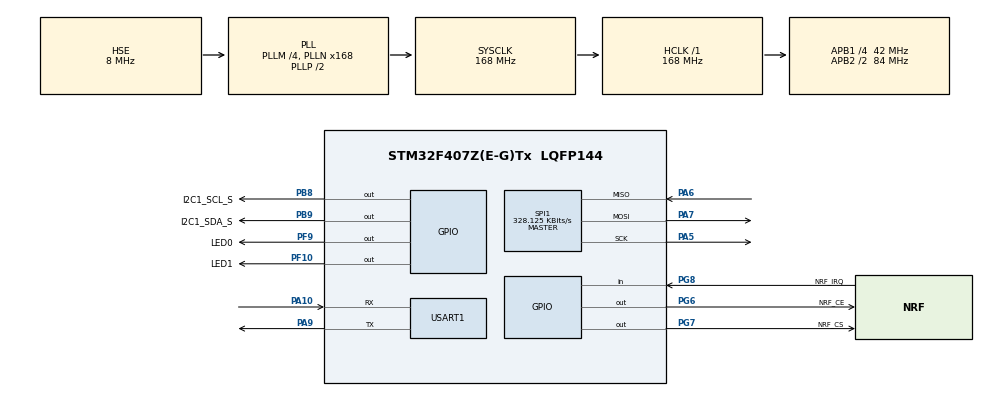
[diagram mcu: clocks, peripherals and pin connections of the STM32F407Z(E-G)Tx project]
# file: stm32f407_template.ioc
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Dma.Request0=USART1_RX
Dma.Request1=USART1_TX
Dma.USART1_RX.0.Direction=DMA_PERIPH_TO_MEMORY
Dma.USART1_RX.0.FIFOMode=DMA_FIFOMODE_DISABLE
Dma.USART1_RX.0.Instance=DMA2_Stream2
Dma.USART1_RX.0.MemDataAlignment=DMA_MDATAALIGN_BYTE
Dma.USART1_RX.0.MemInc=DMA_MINC_ENABLE
Dma.USART1_RX.0.Mode=DMA_CIRCULAR
Dma.USART1_RX.0.PeriphDataAlignment=DMA_PDATAALIGN_BYTE
Dma.USART1_RX.0.PeriphInc=DMA_PINC_DISABLE
Dma.USART1_RX.0.Priority=DMA_PRIORITY_HIGH
Dma.USART1_TX.1.Direction=DMA_MEMORY_TO_PERIPH
Dma.USART1_TX.1.FIFOMode=DMA_FIFOMODE_DISABLE
Dma.USART1_TX.1.Instance=DMA2_Stream7
Dma.USART1_TX.1.MemDataAlignment=DMA_MDATAALIGN_BYTE
Dma.USART1_TX.1.MemInc=DMA_MINC_ENABLE
Dma.USART1_TX.1.Mode=DMA_NORMAL
Dma.USART1_TX.1.PeriphDataAlignment=DMA_PDATAALIGN_BYTE
Dma.USART1_TX.1.PeriphInc=DMA_PINC_DISABLE
Dma.USART1_TX.1.Priority=DMA_PRIORITY_MEDIUM
FREERTOS.INCLUDE_vTaskDelayUntil=1
FREERTOS.Tasks01=defaultTask,0,128,StartDefaultTask,Default,NULL,Dynamic,NULL,NULL
FREERTOS.configMINIMAL_STACK_SIZE=64
Mcu.Family=STM32F4
Mcu.Name=STM32F407Z(E-G)Tx
Mcu.Package=LQFP144
NVIC.DMA2_Stream2_IRQn=true\:5\:0\:false\:false\:true\:true\:false\:true\:true
NVIC.DMA2_Stream7_IRQn=true\:5\:0\:false\:false\:true\:true\:false\:true\:true
NVIC.PriorityGroup=NVIC_PRIORITYGROUP_4
NVIC.TIM6_DAC_IRQn=true\:15\:0\:false\:false\:true\:false\:false\:true\:true
NVIC.TIM7_IRQn=true\:5\:0\:false\:false\:true\:true\:true\:true\:true
NVIC.TimeBase=TIM6_DAC_IRQn
NVIC.TimeBaseIP=TIM6
NVIC.USART1_IRQn=true\:5\:0\:false\:false\:true\:true\:true\:true\:true
PA10.Mode=Asynchronous
PA10.Signal=USART1_RX
PA13.Mode=Serial_Wire
PA13.Signal=SYS_JTMS-SWDIO
PA14.Mode=Serial_Wire
PA14.Signal=SYS_JTCK-SWCLK
PA5.Mode=Full_Duplex_Master
PA5.Signal=SPI1_SCK
PA6.Mode=Full_Duplex_Master
PA6.Signal=SPI1_MISO
PA7.Mode=Full_Duplex_Master
PA7.Signal=SPI1_MOSI
PA9.Mode=Asynchronous
PA9.Signal=USART1_TX
PB8.GPIO_Label=I2C1_SCL_S
PB8.GPIO_PuPd=GPIO_PULLUP
PB8.GPIO_Speed=GPIO_SPEED_FREQ_HIGH
PB8.PinState=GPIO_PIN_SET
PB8.Signal=GPIO_Output
PB9.GPIO_Label=I2C1_SDA_S
PB9.GPIO_PuPd=GPIO_PULLUP
PB9.GPIO_Speed=GPIO_SPEED_FREQ_HIGH
PB9.PinState=GPIO_PIN_SET
PB9.Signal=GPIO_Output
PF10.GPIO_Label=LED1
PF10.GPIO_PuPd=GPIO_PULLUP
PF10.GPIO_Speed=GPIO_SPEED_FREQ_HIGH
PF10.PinState=GPIO_PIN_SET
PF10.Signal=GPIO_Output
PF9.GPIO_Label=LED0
PF9.GPIO_ModeDefaultOutputPP=GPIO_MODE_OUTPUT_PP
PF9.GPIO_PuPd=GPIO_PULLUP
PF9.GPIO_Speed=GPIO_SPEED_FREQ_HIGH
PF9.PinState=GPIO_PIN_SET
PF9.Signal=GPIO_Output
PG6.GPIO_Label=NRF_CE
PG6.GPIO_PuPd=GPIO_PULLUP
PG6.GPIO_Speed=GPIO_SPEED_FREQ_HIGH
PG6.Signal=GPIO_Output
PG7.GPIO_Label=NRF_CS
PG7.GPIO_PuPd=GPIO_PULLUP
PG7.GPIO_Speed=GPIO_SPEED_FREQ_HIGH
PG7.PinState=GPIO_PIN_SET
PG7.Signal=GPIO_Output
PG8.GPIO_Label=NRF_IRQ
PG8.GPIO_PuPd=GPIO_PULLUP
PG8.Signal=GPIO_Input
PH0-OSC_IN.Mode=HSE-External-Oscillator
PH0-OSC_IN.Signal=RCC_OSC_IN
PH1-OSC_OUT.Mode=HSE-External-Oscillator
PH1-OSC_OUT.Signal=RCC_OSC_OUT
ProjectManager.HeapSize=0x200
ProjectManager.StackSize=0x400
ProjectManager.TargetToolchain=MDK-ARM V5.32
RCC.48MHZClocksFreq_Value=84000000
RCC.AHBFreq_Value=168000000
RCC.APB1CLKDivider=RCC_HCLK_DIV4
RCC.APB1Freq_Value=42000000
RCC.APB1TimFreq_Value=84000000
RCC.APB2CLKDivider=RCC_HCLK_DIV2
RCC.APB2Freq_Value=84000000
RCC.APB2TimFreq_Value=168000000
RCC.CortexFreq_Value=168000000
RCC.HCLKFreq_Value=168000000
RCC.HSE_VALUE=8000000
RCC.HSI_VALUE=16000000
RCC.LSE_VALUE=32768
RCC.PLLM=4
RCC.PLLN=168
RCC.PLLSourceVirtual=RCC_PLLSOURCE_HSE
RCC.SYSCLKFreq_VALUE=168000000
RCC.SYSCLKSource=RCC_SYSCLKSOURCE_PLLCLK
RCC.VCOOutputFreq_Value=336000000
SPI1.BaudRatePrescaler=SPI_BAUDRATEPRESCALER_256
SPI1.CLKPhase=SPI_PHASE_2EDGE
SPI1.CalculateBaudRate=328.125 KBits/s
SPI1.Direction=SPI_DIRECTION_2LINES
SPI1.Mode=SPI_MODE_MASTER
SPI1.VirtualType=VM_MASTER
TIM7.Prescaler=83
USART1.VirtualMode=VM_ASYNC
VP_FREERTOS_VS_CMSIS_V1.Mode=CMSIS_V1
VP_SYS_VS_tim6.Mode=TIM6
VP_TIM7_VS_ClockSourceINT.Mode=Enable_Timer
board=custom

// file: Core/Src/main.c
/* USER CODE BEGIN Header */
/**
  ******************************************************************************
  * @file           : main.c
  * @brief          : Main program body
  ******************************************************************************
  * @attention
  *
  * Copyright (c) 2023 STMicroelectronics.
  * All rights reserved.
  *
  * This software is licensed under terms that can be found in the LICENSE file
  * in the root directory of this software component.
  * If no LICENSE file comes with this software, it is provided AS-IS.
  *
  ******************************************************************************
  */
/* USER CODE END Header */
#include "main.h"
#include "cmsis_os.h"

/* USER CODE BEGIN Includes */
#include "system_start.h"
/* USER CODE END Includes */

osThreadId defaultTaskHandle;

void SystemClock_Config(void);
static void MX_GPIO_Init(void);
static void MX_DMA_Init(void);
static void MX_TIM7_Init(void);
static void MX_USART1_UART_Init(void);
static void MX_SPI1_Init(void);
void StartDefaultTask(void const * argument);

int main(void)
{

  /* MCU Configuration--------------------------------------------------------*/

  /* Reset of all peripherals, Initializes the Flash interface and the Systick. */
  HAL_Init();

  /* Configure the system clock */
  SystemClock_Config();

  /* Initialize all configured peripherals */
  MX_GPIO_Init();
  MX_DMA_Init();
  MX_TIM7_Init();
  MX_USART1_UART_Init();
  MX_SPI1_Init();
  /* USER CODE BEGIN 2 */
	System_Init();
  /* USER CODE END 2 */

  /* Create the thread(s) */
  /* definition and creation of defaultTask */
  osThreadDef(defaultTask, StartDefaultTask, osPriorityNormal, 0, 128);
  defaultTaskHandle = osThreadCreate(osThread(defaultTask), NULL);

  /* Start scheduler */
  osKernelStart();

  /* We should never get here as control is now taken by the scheduler */
  /* Infinite loop */
  while (1)
  {

  }
}

void SystemClock_Config(void)
{
  RCC_OscInitTypeDef RCC_OscInitStruct = {0};
  RCC_ClkInitTypeDef RCC_ClkInitStruct = {0};

  /** Configure the main internal regulator output voltage
  */
  __HAL_RCC_PWR_CLK_ENABLE();
  __HAL_PWR_VOLTAGESCALING_CONFIG(PWR_REGULATOR_VOLTAGE_SCALE1);

  /** Initializes the RCC Oscillators according to the specified parameters
  * in the RCC_OscInitTypeDef structure.
  */
  RCC_OscInitStruct.OscillatorType = RCC_OSCILLATORTYPE_HSE;
  RCC_OscInitStruct.HSEState = RCC_HSE_ON;
  RCC_OscInitStruct.PLL.PLLState = RCC_PLL_ON;
  RCC_OscInitStruct.PLL.PLLSource = RCC_PLLSOURCE_HSE;
  RCC_OscInitStruct.PLL.PLLM = 4;
  RCC_OscInitStruct.PLL.PLLN = 168;
  RCC_OscInitStruct.PLL.PLLP = RCC_PLLP_DIV2;
  RCC_OscInitStruct.PLL.PLLQ = 4;
  if (HAL_RCC_OscConfig(&RCC_OscInitStruct) != HAL_OK)
  {
    Error_Handler();
  }

  /** Initializes the CPU, AHB and APB buses clocks
  */
  RCC_ClkInitStruct.ClockType = RCC_CLOCKTYPE_HCLK|RCC_CLOCKTYPE_SYSCLK
                              |RCC_CLOCKTYPE_PCLK1|RCC_CLOCKTYPE_PCLK2;
  RCC_ClkInitStruct.SYSCLKSource = RCC_SYSCLKSOURCE_PLLCLK;
  RCC_ClkInitStruct.AHBCLKDivider = RCC_SYSCLK_DIV1;
  RCC_ClkInitStruct.APB1CLKDivider = RCC_HCLK_DIV4;
  RCC_ClkInitStruct.APB2CLKDivider = RCC_HCLK_DIV2;

  if (HAL_RCC_ClockConfig(&RCC_ClkInitStruct, FLASH_LATENCY_5) != HAL_OK)
  {
    Error_Handler();
  }
}

static void MX_SPI1_Init(void)
{

  LL_SPI_InitTypeDef SPI_InitStruct = {0};

  LL_GPIO_InitTypeDef GPIO_InitStruct = {0};

  /* Peripheral clock enable */
  LL_APB2_GRP1_EnableClock(LL_APB2_GRP1_PERIPH_SPI1);

  LL_AHB1_GRP1_EnableClock(LL_AHB1_GRP1_PERIPH_GPIOA);
  /**SPI1 GPIO Configuration
  PA5   ------> SPI1_SCK
  PA6   ------> SPI1_MISO
  PA7   ------> SPI1_MOSI
  */
  GPIO_InitStruct.Pin = LL_GPIO_PIN_5|LL_GPIO_PIN_6|LL_GPIO_PIN_7;
  GPIO_InitStruct.Mode = LL_GPIO_MODE_ALTERNATE;
  GPIO_InitStruct.Speed = LL_GPIO_SPEED_FREQ_VERY_HIGH;
  GPIO_InitStruct.OutputType = LL_GPIO_OUTPUT_PUSHPULL;
  GPIO_InitStruct.Pull = LL_GPIO_PULL_NO;
  GPIO_InitStruct.Alternate = LL_GPIO_AF_5;
  LL_GPIO_Init(GPIOA, &GPIO_InitStruct);

  /* SPI1 parameter configuration*/
  SPI_InitStruct.TransferDirection = LL_SPI_FULL_DUPLEX;
  SPI_InitStruct.Mode = LL_SPI_MODE_MASTER;
  SPI_InitStruct.DataWidth = LL_SPI_DATAWIDTH_8BIT;
  SPI_InitStruct.ClockPolarity = LL_SPI_POLARITY_LOW;
  SPI_InitStruct.ClockPhase = LL_SPI_PHASE_2EDGE;
  SPI_InitStruct.NSS = LL_SPI_NSS_SOFT;
  SPI_InitStruct.BaudRate = LL_SPI_BAUDRATEPRESCALER_DIV256;
  SPI_InitStruct.BitOrder = LL_SPI_MSB_FIRST;
  SPI_InitStruct.CRCCalculation = LL_SPI_CRCCALCULATION_DISABLE;
  SPI_InitStruct.CRCPoly = 10;
  LL_SPI_Init(SPI1, &SPI_InitStruct);
  LL_SPI_SetStandard(SPI1, LL_SPI_PROTOCOL_MOTOROLA);

}

static void MX_TIM7_Init(void)
{

  LL_TIM_InitTypeDef TIM_InitStruct = {0};

  /* Peripheral clock enable */
  LL_APB1_GRP1_EnableClock(LL_APB1_GRP1_PERIPH_TIM7);

  /* TIM7 interrupt Init */
  NVIC_SetPriority(TIM7_IRQn, NVIC_EncodePriority(NVIC_GetPriorityGrouping(),5, 0));
  NVIC_EnableIRQ(TIM7_IRQn);

  TIM_InitStruct.Prescaler = 83;
  TIM_InitStruct.CounterMode = LL_TIM_COUNTERMODE_UP;
  TIM_InitStruct.Autoreload = 65535;
  LL_TIM_Init(TIM7, &TIM_InitStruct);
  LL_TIM_DisableARRPreload(TIM7);
  LL_TIM_SetTriggerOutput(TIM7, LL_TIM_TRGO_RESET);
  LL_TIM_DisableMasterSlaveMode(TIM7);

}

static void MX_USART1_UART_Init(void)
{

  LL_USART_InitTypeDef USART_InitStruct = {0};

  LL_GPIO_InitTypeDef GPIO_InitStruct = {0};

  /* Peripheral clock enable */
  LL_APB2_GRP1_EnableClock(LL_APB2_GRP1_PERIPH_USART1);

  LL_AHB1_GRP1_EnableClock(LL_AHB1_GRP1_PERIPH_GPIOA);
  /**USART1 GPIO Configuration
  PA9   ------> USART1_TX
  PA10   ------> USART1_RX
  */
  GPIO_InitStruct.Pin = LL_GPIO_PIN_9|LL_GPIO_PIN_10;
  GPIO_InitStruct.Mode = LL_GPIO_MODE_ALTERNATE;
  GPIO_InitStruct.Speed = LL_GPIO_SPEED_FREQ_VERY_HIGH;
  GPIO_InitStruct.OutputType = LL_GPIO_OUTPUT_PUSHPULL;
  GPIO_InitStruct.Pull = LL_GPIO_PULL_NO;
  GPIO_InitStruct.Alternate = LL_GPIO_AF_7;
  LL_GPIO_Init(GPIOA, &GPIO_InitStruct);

  /* USART1 DMA Init */

  /* USART1_RX Init */
  LL_DMA_SetChannelSelection(DMA2, LL_DMA_STREAM_2, LL_DMA_CHANNEL_4);

  LL_DMA_SetDataTransferDirection(DMA2, LL_DMA_STREAM_2, LL_DMA_DIRECTION_PERIPH_TO_MEMORY);

  LL_DMA_SetStreamPriorityLevel(DMA2, LL_DMA_STREAM_2, LL_DMA_PRIORITY_HIGH);

  LL_DMA_SetMode(DMA2, LL_DMA_STREAM_2, LL_DMA_MODE_CIRCULAR);

  LL_DMA_SetPeriphIncMode(DMA2, LL_DMA_STREAM_2, LL_DMA_PERIPH_NOINCREMENT);

  LL_DMA_SetMemoryIncMode(DMA2, LL_DMA_STREAM_2, LL_DMA_MEMORY_INCREMENT);

  LL_DMA_SetPeriphSize(DMA2, LL_DMA_STREAM_2, LL_DMA_PDATAALIGN_BYTE);

  LL_DMA_SetMemorySize(DMA2, LL_DMA_STREAM_2, LL_DMA_MDATAALIGN_BYTE);

  LL_DMA_DisableFifoMode(DMA2, LL_DMA_STREAM_2);

  /* USART1_TX Init */
  LL_DMA_SetChannelSelection(DMA2, LL_DMA_STREAM_7, LL_DMA_CHANNEL_4);

  LL_DMA_SetDataTransferDirection(DMA2, LL_DMA_STREAM_7, LL_DMA_DIRECTION_MEMORY_TO_PERIPH);

  LL_DMA_SetStreamPriorityLevel(DMA2, LL_DMA_STREAM_7, LL_DMA_PRIORITY_MEDIUM);

  LL_DMA_SetMode(DMA2, LL_DMA_STREAM_7, LL_DMA_MODE_NORMAL);

  LL_DMA_SetPeriphIncMode(DMA2, LL_DMA_STREAM_7, LL_DMA_PERIPH_NOINCREMENT);

  LL_DMA_SetMemoryIncMode(DMA2, LL_DMA_STREAM_7, LL_DMA_MEMORY_INCREMENT);

  LL_DMA_SetPeriphSize(DMA2, LL_DMA_STREAM_7, LL_DMA_PDATAALIGN_BYTE);

  LL_DMA_SetMemorySize(DMA2, LL_DMA_STREAM_7, LL_DMA_MDATAALIGN_BYTE);

  LL_DMA_DisableFifoMode(DMA2, LL_DMA_STREAM_7);

  /* USART1 interrupt Init */
  NVIC_SetPriority(USART1_IRQn, NVIC_EncodePriority(NVIC_GetPriorityGrouping(),5, 0));
  NVIC_EnableIRQ(USART1_IRQn);

  USART_InitStruct.BaudRate = 115200;
  USART_InitStruct.DataWidth = LL_USART_DATAWIDTH_8B;
  USART_InitStruct.StopBits = LL_USART_STOPBITS_1;
  USART_InitStruct.Parity = LL_USART_PARITY_NONE;
  USART_InitStruct.TransferDirection = LL_USART_DIRECTION_TX_RX;
  USART_InitStruct.HardwareFlowControl = LL_USART_HWCONTROL_NONE;
  USART_InitStruct.OverSampling = LL_USART_OVERSAMPLING_16;
  LL_USART_Init(USART1, &USART_InitStruct);
  LL_USART_ConfigAsyncMode(USART1);
  LL_USART_Enable(USART1);

}

static void MX_DMA_Init(void)
{

  /* Init with LL driver */
  /* DMA controller clock enable */
  LL_AHB1_GRP1_EnableClock(LL_AHB1_GRP1_PERIPH_DMA2);

  /* DMA interrupt init */
  /* DMA2_Stream2_IRQn interrupt configuration */
  NVIC_SetPriority(DMA2_Stream2_IRQn, NVIC_EncodePriority(NVIC_GetPriorityGrouping(),5, 0));
  NVIC_EnableIRQ(DMA2_Stream2_IRQn);
  /* DMA2_Stream7_IRQn interrupt configuration */
  NVIC_SetPriority(DMA2_Stream7_IRQn, NVIC_EncodePriority(NVIC_GetPriorityGrouping(),5, 0));
  NVIC_EnableIRQ(DMA2_Stream7_IRQn);

}

static void MX_GPIO_Init(void)
{
  GPIO_InitTypeDef GPIO_InitStruct = {0};

  /* GPIO Ports Clock Enable */
  __HAL_RCC_GPIOF_CLK_ENABLE();
  __HAL_RCC_GPIOH_CLK_ENABLE();
  __HAL_RCC_GPIOA_CLK_ENABLE();
  __HAL_RCC_GPIOG_CLK_ENABLE();
  __HAL_RCC_GPIOB_CLK_ENABLE();

  /*Configure GPIO pin Output Level */
  HAL_GPIO_WritePin(GPIOF, LED0_Pin|LED1_Pin, GPIO_PIN_SET);

  /*Configure GPIO pin Output Level */
  HAL_GPIO_WritePin(NRF_CE_GPIO_Port, NRF_CE_Pin, GPIO_PIN_RESET);

  /*Configure GPIO pin Output Level */
  HAL_GPIO_WritePin(NRF_CS_GPIO_Port, NRF_CS_Pin, GPIO_PIN_SET);

  /*Configure GPIO pin Output Level */
  HAL_GPIO_WritePin(GPIOB, I2C1_SCL_S_Pin|I2C1_SDA_S_Pin, GPIO_PIN_SET);

  /*Configure GPIO pins : LED0_Pin LED1_Pin */
  GPIO_InitStruct.Pin = LED0_Pin|LED1_Pin;
  GPIO_InitStruct.Mode = GPIO_MODE_OUTPUT_PP;
  GPIO_InitStruct.Pull = GPIO_PULLUP;
  GPIO_InitStruct.Speed = GPIO_SPEED_FREQ_HIGH;
  HAL_GPIO_Init(GPIOF, &GPIO_InitStruct);

  /*Configure GPIO pins : NRF_CE_Pin NRF_CS_Pin */
  GPIO_InitStruct.Pin = NRF_CE_Pin|NRF_CS_Pin;
  GPIO_InitStruct.Mode = GPIO_MODE_OUTPUT_PP;
  GPIO_InitStruct.Pull = GPIO_PULLUP;
  GPIO_InitStruct.Speed = GPIO_SPEED_FREQ_HIGH;
  HAL_GPIO_Init(GPIOG, &GPIO_InitStruct);

  /*Configure GPIO pin : NRF_IRQ_Pin */
  GPIO_InitStruct.Pin = NRF_IRQ_Pin;
  GPIO_InitStruct.Mode = GPIO_MODE_INPUT;
  GPIO_InitStruct.Pull = GPIO_PULLUP;
  HAL_GPIO_Init(NRF_IRQ_GPIO_Port, &GPIO_InitStruct);

  /*Configure GPIO pins : I2C1_SCL_S_Pin I2C1_SDA_S_Pin */
  GPIO_InitStruct.Pin = I2C1_SCL_S_Pin|I2C1_SDA_S_Pin;
  GPIO_InitStruct.Mode = GPIO_MODE_OUTPUT_PP;
  GPIO_InitStruct.Pull = GPIO_PULLUP;
  GPIO_InitStruct.Speed = GPIO_SPEED_FREQ_HIGH;
  HAL_GPIO_Init(GPIOB, &GPIO_InitStruct);

}

void StartDefaultTask(void const * argument)
{
  /* USER CODE BEGIN 5 */
  /* Infinite loop */
  for(;;)
  {
		RTOS_Init();
    osThreadTerminate (defaultTaskHandle);
  }
  /* USER CODE END 5 */
}

void HAL_TIM_PeriodElapsedCallback(TIM_HandleTypeDef *htim)
{
  if (htim->Instance == TIM6) {
    HAL_IncTick();
  }
}

void Error_Handler(void)
{
  __disable_irq();
  while (1)
  {
  }
}
